# LM3S618 register map
File version: 7944
Registers are 32-bit, read-write, no defined reset value unless marked. A register's access mark holds for its fields unless they carry their own. Offsets are from the block's base; [hi:lo] are bit positions.

## QEI0 — Register map for QEI0 peripheral
Base 0x4002C000; register names take the prefix QEI0
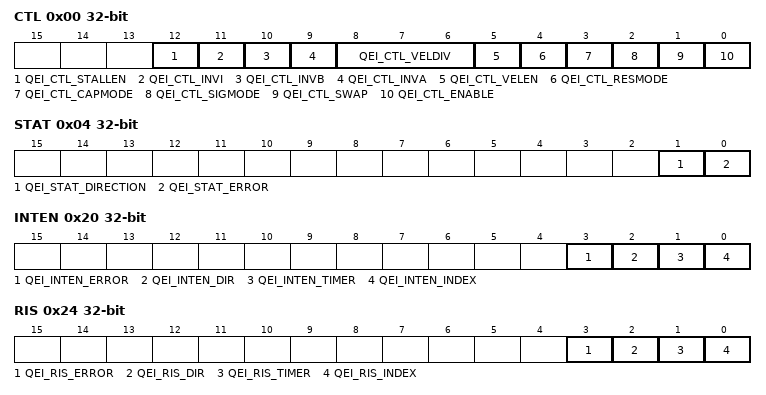
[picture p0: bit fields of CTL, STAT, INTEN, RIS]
0x00 CTL — QEI Control
  [12] QEI_CTL_STALLEN — Stall QEI
  [11] QEI_CTL_INVI — Invert Index Pulse
  [10] QEI_CTL_INVB — Invert PhB
  [9] QEI_CTL_INVA — Invert PhA
  [8:6] QEI_CTL_VELDIV — Predivide Velocity
    0=QEI clock /1; 1=QEI clock /2; 2=QEI clock /4; 3=QEI clock /8; 4=QEI clock /16; 5=QEI clock /32; 6=QEI clock /64; 7=QEI clock /128
  [5] QEI_CTL_VELEN — Capture Velocity
  [4] QEI_CTL_RESMODE — Reset Mode
  [3] QEI_CTL_CAPMODE — Capture Mode
  [2] QEI_CTL_SIGMODE — Signal Mode
  [1] QEI_CTL_SWAP — Swap Signals
  [0] QEI_CTL_ENABLE — Enable QEI
0x04 STAT — QEI Status
  [1] QEI_STAT_DIRECTION — Direction of Rotation
  [0] QEI_STAT_ERROR — Error Detected
0x08 POS — QEI Position
  [31:0] QEI_POS — Current Position Integrator Value
0x0C MAXPOS — QEI Maximum Position
  [31:0] QEI_MAXPOS — Maximum Position Integrator Value
0x10 LOAD — QEI Timer Load
  [31:0] QEI_LOAD — Velocity Timer Load Value
0x14 TIME — QEI Timer
  [31:0] QEI_TIME — Velocity Timer Current Value
0x18 COUNT — QEI Velocity Counter
  [31:0] QEI_COUNT — Velocity Pulse Count
0x1C SPEED — QEI Velocity
  [31:0] QEI_SPEED — Velocity
0x20 INTEN — QEI Interrupt Enable
  [3] QEI_INTEN_ERROR — Phase Error Interrupt Enable
  [2] QEI_INTEN_DIR — Direction Change Interrupt Enable
  [1] QEI_INTEN_TIMER — Timer Expires Interrupt Enable
  [0] QEI_INTEN_INDEX — Index Pulse Detected Interrupt Enable
0x24 RIS — QEI Raw Interrupt Status
  [3] QEI_RIS_ERROR — Phase Error Detected
  [2] QEI_RIS_DIR — Direction Change Detected
  [1] QEI_RIS_TIMER — Velocity Timer Expired
  [0] QEI_RIS_INDEX — Index Pulse Asserted
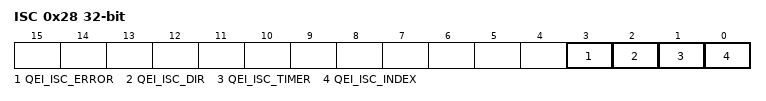
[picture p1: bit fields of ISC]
0x28 ISC — QEI Interrupt Status and Clear
  [3] QEI_ISC_ERROR — Phase Error Interrupt
  [2] QEI_ISC_DIR — Direction Change Interrupt
  [1] QEI_ISC_TIMER — Velocity Timer Expired Interrupt
  [0] QEI_ISC_INDEX — Index Pulse Interrupt

## COMP — Register map for COMP peripheral
Base 0x4003C000; register names take the prefix COMP
0x00 ACMIS — Analog Comparator Masked Interrupt Status
  [0] COMP_ACMIS_IN0 — Comparator 0 Masked Interrupt Status
0x04 ACRIS — Analog Comparator Raw Interrupt Status
  [0] COMP_ACRIS_IN0 — Comparator 0 Interrupt Status
0x08 ACINTEN — Analog Comparator Interrupt Enable
  [0] COMP_ACINTEN_IN0 — Comparator 0 Interrupt Enable
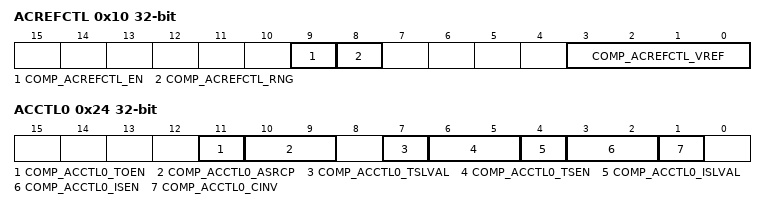
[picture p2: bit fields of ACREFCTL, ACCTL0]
0x10 ACREFCTL — Analog Comparator Reference Voltage Control
  [9] COMP_ACREFCTL_EN — Resistor Ladder Enable
  [8] COMP_ACREFCTL_RNG — Resistor Ladder Range
  [3:0] COMP_ACREFCTL_VREF — Resistor Ladder Voltage Ref
0x20 ACSTAT0 — Analog Comparator Status 0
  [1] COMP_ACSTAT0_OVAL — Comparator Output Value
0x24 ACCTL0 — Analog Comparator Control 0
  [11] COMP_ACCTL0_TOEN — Trigger Output Enable
  [10:9] COMP_ACCTL0_ASRCP — Analog Source Positive
    0=COMP_ACCTL0_ASRCP_PIN (Pin value of Cn+); 1=COMP_ACCTL0_ASRCP_PIN0 (Pin value of C0+); 2=COMP_ACCTL0_ASRCP_REF (Internal voltage reference (VIREF))
  [7] COMP_ACCTL0_TSLVAL — Trigger Sense Level Value
  [6:5] COMP_ACCTL0_TSEN — Trigger Sense
    0=COMP_ACCTL0_TSEN_LEVEL (Level sense, see TSLVAL); 1=COMP_ACCTL0_TSEN_FALL (Falling edge); 2=COMP_ACCTL0_TSEN_RISE (Rising edge); 3=COMP_ACCTL0_TSEN_BOTH (Either edge)
  [4] COMP_ACCTL0_ISLVAL — Interrupt Sense Level Value
  [3:2] COMP_ACCTL0_ISEN — Interrupt Sense
    0=COMP_ACCTL0_ISEN_LEVEL (Level sense, see ISLVAL); 1=COMP_ACCTL0_ISEN_FALL (Falling edge); 2=COMP_ACCTL0_ISEN_RISE (Rising edge); 3=COMP_ACCTL0_ISEN_BOTH (Either edge)
  [1] COMP_ACCTL0_CINV — Comparator Output Invert

## FLASH_CTRL — Register map for FLASH_CTRL peripheral
Base 0x400FD000; register names take the prefix FLASH_CTRL
0x00 FMA — Flash Memory Address
  [14:0] FLASH_FMA_OFFSET — Address Offset
0x04 FMD — Flash Memory Data
  [31:0] FLASH_FMD_DATA — Data Value
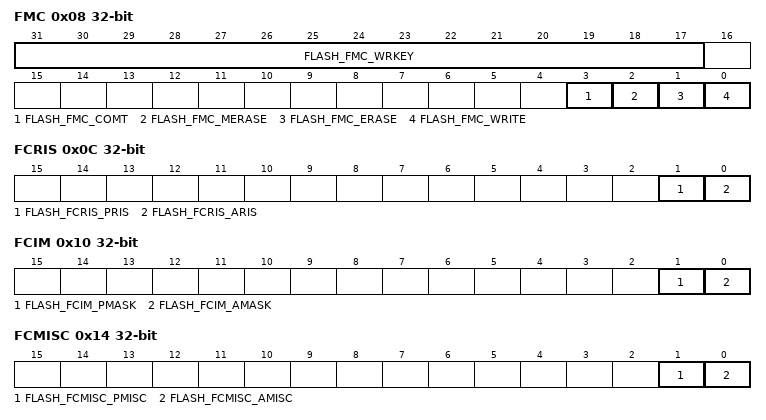
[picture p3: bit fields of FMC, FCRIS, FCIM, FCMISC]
0x08 FMC — Flash Memory Control
  [31:17] FLASH_FMC_WRKEY — FLASH write key
  [3] FLASH_FMC_COMT — Commit Register Value
  [2] FLASH_FMC_MERASE — Mass Erase Flash Memory
  [1] FLASH_FMC_ERASE — Erase a Page of Flash Memory
  [0] FLASH_FMC_WRITE — Write a Word into Flash Memory
0x0C FCRIS — Flash Controller Raw Interrupt Status
  [1] FLASH_FCRIS_PRIS — Programming Raw Interrupt Status
  [0] FLASH_FCRIS_ARIS — Access Raw Interrupt Status
0x10 FCIM — Flash Controller Interrupt Mask
  [1] FLASH_FCIM_PMASK — Programming Interrupt Mask
  [0] FLASH_FCIM_AMASK — Access Interrupt Mask
0x14 FCMISC — Flash Controller Masked Interrupt Status and Clear
  [1] FLASH_FCMISC_PMISC — Programming Masked Interrupt Status and Clear
  [0] FLASH_FCMISC_AMISC — Access Masked Interrupt Status and Clear
0x1130 FMPRE — Flash Memory Protection Read Enable
0x1134 FMPPE — Flash Memory Protection Program Enable
0x1140 USECRL — USec Reload
  [7:0] FLASH_USECRL — Microsecond Reload Value
